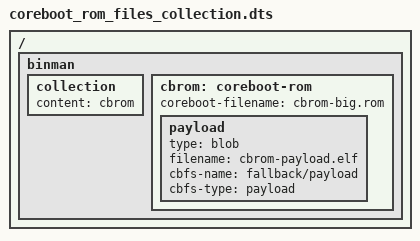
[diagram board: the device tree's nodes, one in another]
// SPDX-License-Identifier: GPL-2.0+

/dts-v1/;

/ {
	#address-cells = <1>;
	#size-cells = <1>;

	binman {
		collection {
			content = <&cbrom>;
		};
		cbrom: coreboot-rom {
			coreboot-filename = "cbrom-big.rom";
			payload {
				type = "blob";
				filename = "cbrom-payload.elf";
				cbfs-name = "fallback/payload";
				cbfs-type = "payload";
			};
		};
	};
};
